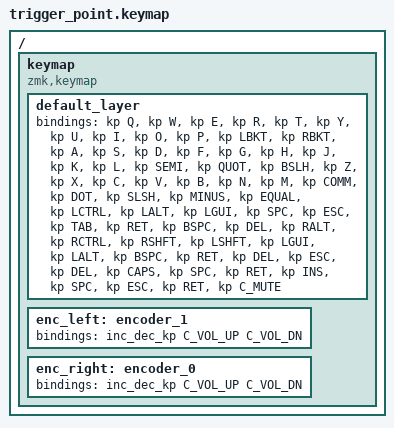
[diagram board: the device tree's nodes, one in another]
#include <dt-bindings/zmk/keys.h>

/ {
  keymap {
    compatible = "zmk,keymap";

    default_layer {
      bindings = <
        &kp Q  &kp W  &kp E  &kp R  &kp T  &kp Y  &kp U  &kp I  &kp O  &kp P  &kp LBKT  &kp RBKT
        &kp A  &kp S  &kp D  &kp F  &kp G  &kp H  &kp J  &kp K  &kp L  &kp SEMI &kp QUOT &kp BSLH
        &kp Z  &kp X  &kp C  &kp V  &kp B  &kp N  &kp M  &kp COMM &kp DOT &kp SLSH &kp MINUS &kp EQUAL

        &kp LCTRL &kp LALT &kp LGUI &kp SPC
        &kp ESC   &kp TAB  &kp RET  &kp BSPC &kp DEL
        &kp RALT  &kp RCTRL &kp RSHFT

        &kp LSHFT &kp LGUI &kp LALT &kp BSPC &kp RET  &kp DEL  &kp ESC &kp DEL &kp CAPS &kp SPC &kp RET &kp INS

        &kp SPC
        &kp ESC
        &kp RET
        &kp C_MUTE
      >;
    };

    enc_left:  encoder_1 { bindings = <&inc_dec_kp C_VOL_UP C_VOL_DN>; };
    enc_right: encoder_0 { bindings = <&inc_dec_kp C_VOL_UP C_VOL_DN>; };
  };
};
